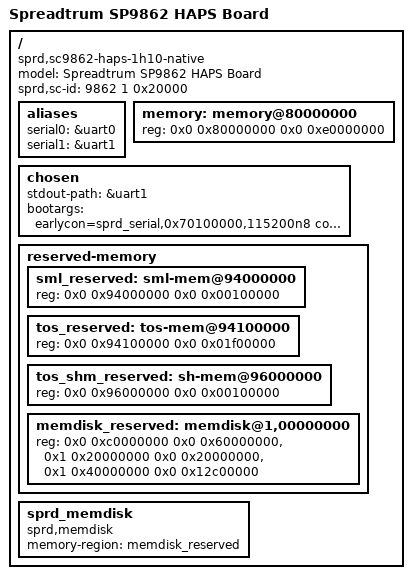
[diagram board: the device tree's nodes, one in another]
/*
 * Spreadtrum SP9862_HAPS board DTS file
 *
 * Copyright (C) 2016, Spreadtrum Communications Inc.
 *
 * This file is licensed under a dual GPLv2 or X11 license.
 */

/dts-v1/;

#include "sc9862haps.dtsi"
#include "sp9862haps-common.dtsi"

/ {
	model = "Spreadtrum SP9862 HAPS Board";
	compatible = "sprd,sc9862-haps-1h10-native";
	sprd,sc-id = <9862 1 0x20000>;
	#address-cells = <2>;
	#size-cells = <2>;

	aliases {
		serial0 = &uart0;
		serial1 = &uart1;
	};

	memory: memory@80000000 {
		device_type = "memory";
		reg = <0x0 0x80000000 0x0 0xe0000000>;
	};

	chosen {
		stdout-path = &uart1;
		bootargs = "earlycon=sprd_serial,0x70100000,115200n8 console=ttyS1,115200n8 loglevel=8 maxcpus=1 init=/init root=/dev/ram0 rw androidboot.hardware=sp9862_haps androidboot.selinux=permissive";
	};

	reserved-memory {
		#address-cells = <2>;
		#size-cells = <2>;
		ranges;

		/* must be 64M aligned */
		sml_reserved: sml-mem@94000000{
		    reg = <0x0 0x94000000 0x0 0x00100000>;
		};

		tos_reserved: tos-mem@94100000{
		    reg = <0x0 0x94100000 0x0 0x01f00000>;
		};

		tos_shm_reserved: sh-mem@96000000{
		    reg = <0x0 0x96000000 0x0 0x00100000>;
		};


		memdisk_reserved: memdisk@1,00000000{
			reg = <0x0 0xc0000000 0x0 0x60000000>,	/* system */
				<0x1 0x20000000 0x0 0x20000000>, /* userdata */
				<0x1 0x40000000 0x0 0x12c00000>; /* vendor */
		};
	};

	sprd_memdisk {
		compatible = "sprd,memdisk";
		memory-region = <&memdisk_reserved>;
	};
};

